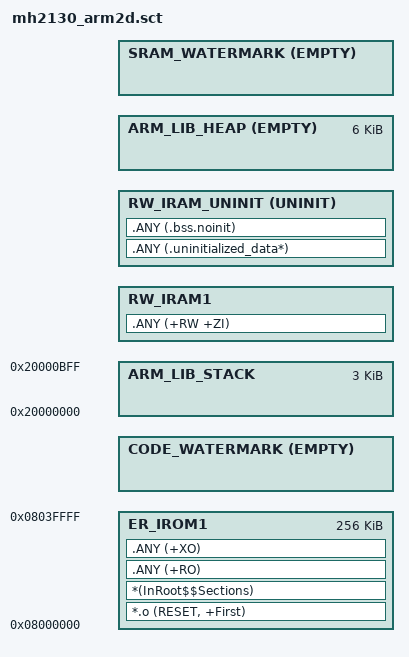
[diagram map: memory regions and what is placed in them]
#! armclang --target=arm-arm-none-eabi -mcpu=cortex-m3 -E -xc
; *************************************************************
; *** Scatter-Loading Description File generated by uVision ***
; *************************************************************

#define CODE_START      0x08000000
#define CODE_SIZE       0x00040000

#define RAM0_START      0x20000000
#define RAM0_SIZE       0x00010000

#define STACK_SIZE      0x00000C00
#define HEAP_SIZE       0x00001800

LR_IROM1 CODE_START CODE_SIZE  {    ; load region size_region
    ER_IROM1 CODE_START  CODE_SIZE {  ; load address = execution address
        *.o (RESET, +First)
        *(InRoot$$Sections)
        .ANY (+RO)
        .ANY (+XO)
    }

    /* This empty, zero long execution region is here to mark the limit address
     * of the last execution region that is allocated in SRAM.
     */
    CODE_WATERMARK +0 EMPTY 0x0 {
    }
    /* Make sure that the sections allocated in the SRAM does not exceed the
     * size of the SRAM available.
     */
    ScatterAssert(ImageLimit(CODE_WATERMARK) <= CODE_START + CODE_SIZE)
    

    ARM_LIB_STACK RAM0_START ALIGN 32 FILL 0xDEADBEEF STACK_SIZE {   ; Reserve empty region for stack
    }

    RW_IRAM1 +0  {  ; RW data
        .ANY (+RW +ZI)
    }

    RW_IRAM_UNINIT +0 UNINIT {
        .ANY (.uninitialized_data*)
        .ANY (.bss.noinit)
    }

    #if HEAP_SIZE > 0
    ARM_LIB_HEAP +0 ALIGN 8 EMPTY  HEAP_SIZE  {   ; Reserve empty region for heap
    }
    #endif

    /* This empty, zero long execution region is here to mark the limit address
     * of the last execution region that is allocated in SRAM.
     */
    SRAM_WATERMARK +0 EMPTY 0x0 {
    }
    /* Make sure that the sections allocated in the SRAM does not exceed the
     * size of the SRAM available.
     */
    ScatterAssert(ImageLimit(SRAM_WATERMARK) <= RAM0_START + RAM0_SIZE)
}

